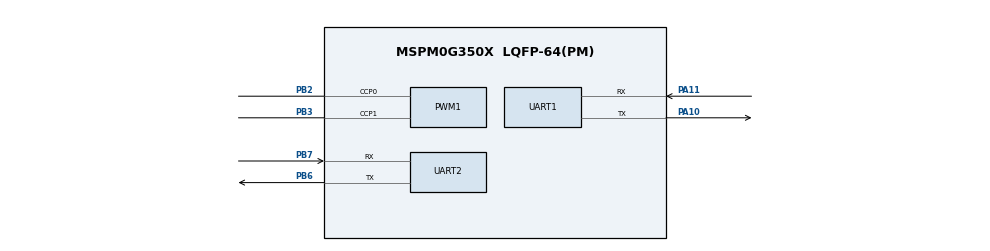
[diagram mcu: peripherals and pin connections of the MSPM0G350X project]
/**
 * @cliArgs --device "MSPM0G350X" --package "LQFP-64(PM)" --part "Default" --product "mspm0_sdk@2.01.00.03"
 * @versions {"tool":"1.20.0+3587"}
 */

/**
 * Import the modules used in this configuration.
 */
const Board   = scripting.addModule("/ti/driverlib/Board");
const GPIO    = scripting.addModule("/ti/driverlib/GPIO", {}, false);
const GPIO1   = GPIO.addInstance();
const GPIO2   = GPIO.addInstance();
const GPIO3   = GPIO.addInstance();
const GPIO4   = GPIO.addInstance();
const GPIO5   = GPIO.addInstance();
const GPIO6   = GPIO.addInstance();
const GPIO7   = GPIO.addInstance();
const GPIO8   = GPIO.addInstance();
const GPIO9   = GPIO.addInstance();
const GPIO10  = GPIO.addInstance();
const GPIO11  = GPIO.addInstance();
const GPIO12  = GPIO.addInstance();
const I2C     = scripting.addModule("/ti/driverlib/I2C", {}, false);
const I2C1    = I2C.addInstance();
const PWM     = scripting.addModule("/ti/driverlib/PWM", {}, false);
const PWM1    = PWM.addInstance();
const SYSCTL  = scripting.addModule("/ti/driverlib/SYSCTL");
const SYSTICK = scripting.addModule("/ti/driverlib/SYSTICK");
const TIMER   = scripting.addModule("/ti/driverlib/TIMER", {}, false);
const TIMER1  = TIMER.addInstance();
const UART    = scripting.addModule("/ti/driverlib/UART", {}, false);
const UART1   = UART.addInstance();
const UART2   = UART.addInstance();

/**
 * Write custom configuration values to the imported modules.
 */
const divider7       = system.clockTree["PLL_PDIV"];
divider7.divideValue = 2;

const divider9       = system.clockTree["UDIV"];
divider9.divideValue = 2;

const gate7  = system.clockTree["MFCLKGATE"];
gate7.enable = true;

const multiplier2         = system.clockTree["PLL_QDIV"];
multiplier2.multiplyValue = 5;

const mux8       = system.clockTree["HSCLKMUX"];
mux8.inputSelect = "HSCLKMUX_SYSPLL2X";

const pinFunction4     = system.clockTree["HFXT"];
pinFunction4.inputFreq = 40;
pinFunction4.enable    = true;


GPIO1.$name                          = "AIN";
GPIO1.associatedPins.create(2);
GPIO1.associatedPins[0].$name        = "AIN1";
GPIO1.associatedPins[0].assignedPort = "PORTA";
GPIO1.associatedPins[0].assignedPin  = "14";
GPIO1.associatedPins[1].$name        = "AIN2";
GPIO1.associatedPins[1].assignedPort = "PORTA";
GPIO1.associatedPins[1].assignedPin  = "13";

GPIO2.$name                          = "LED";
GPIO2.associatedPins[0].$name        = "led";
GPIO2.associatedPins[0].assignedPort = "PORTB";
GPIO2.associatedPins[0].assignedPin  = "9";

GPIO3.$name                          = "BIN";
GPIO3.associatedPins.create(2);
GPIO3.associatedPins[0].$name        = "BIN1";
GPIO3.associatedPins[0].assignedPin  = "17";
GPIO3.associatedPins[0].assignedPort = "PORTA";
GPIO3.associatedPins[1].$name        = "BIN2";
GPIO3.associatedPins[1].assignedPort = "PORTA";
GPIO3.associatedPins[1].assignedPin  = "16";

GPIO4.$name                         = "ENCODERA";
GPIO4.port                          = "PORTA";
GPIO4.associatedPins.create(2);
GPIO4.associatedPins[0].$name       = "E1A";
GPIO4.associatedPins[0].direction   = "INPUT";
GPIO4.associatedPins[0].assignedPin = "25";
GPIO4.associatedPins[0].interruptEn = true;
GPIO4.associatedPins[0].polarity    = "RISE";
GPIO4.associatedPins[1].$name       = "E1B";
GPIO4.associatedPins[1].direction   = "INPUT";
GPIO4.associatedPins[1].assignedPin = "26";
GPIO4.associatedPins[1].interruptEn = true;
GPIO4.associatedPins[1].polarity    = "RISE";

GPIO5.$name                         = "ENCODERB";
GPIO5.port                          = "PORTB";
GPIO5.associatedPins.create(2);
GPIO5.associatedPins[0].$name       = "E2A";
GPIO5.associatedPins[0].direction   = "INPUT";
GPIO5.associatedPins[0].assignedPin = "20";
GPIO5.associatedPins[0].interruptEn = true;
GPIO5.associatedPins[0].polarity    = "RISE";
GPIO5.associatedPins[1].$name       = "E2B";
GPIO5.associatedPins[1].direction   = "INPUT";
GPIO5.associatedPins[1].assignedPin = "24";
GPIO5.associatedPins[1].interruptEn = true;
GPIO5.associatedPins[1].polarity    = "RISE";

GPIO6.$name                          = "OLED_RST";
GPIO6.associatedPins[0].$name        = "PIN_RST";
GPIO6.associatedPins[0].assignedPort = "PORTB";
GPIO6.associatedPins[0].assignedPin  = "14";

GPIO7.$name                          = "OLED_DC";
GPIO7.associatedPins[0].$name        = "PIN_DC";
GPIO7.associatedPins[0].assignedPort = "PORTB";
GPIO7.associatedPins[0].assignedPin  = "15";

GPIO8.$name                          = "OLED_SCL";
GPIO8.associatedPins[0].$name        = "PIN_SCL";
GPIO8.associatedPins[0].assignedPort = "PORTA";
GPIO8.associatedPins[0].assignedPin  = "28";

GPIO9.$name                          = "OLED_SDA";
GPIO9.associatedPins[0].$name        = "PIN_SDA";
GPIO9.associatedPins[0].assignedPort = "PORTA";
GPIO9.associatedPins[0].assignedPin  = "31";

GPIO10.$name                          = "MPU_INT";
GPIO10.associatedPins[0].$name        = "INT";
GPIO10.associatedPins[0].direction    = "INPUT";
GPIO10.associatedPins[0].assignedPort = "PORTA";
GPIO10.associatedPins[0].assignedPin  = "7";
GPIO10.associatedPins[0].polarity     = "RISE";
GPIO10.associatedPins[0].interruptEn  = true;

GPIO11.$name                              = "TRACK";
GPIO11.associatedPins.create(7);
GPIO11.associatedPins[0].$name            = "S2";
GPIO11.associatedPins[0].direction        = "INPUT";
GPIO11.associatedPins[0].internalResistor = "PULL_UP";
GPIO11.associatedPins[0].assignedPort     = "PORTB";
GPIO11.associatedPins[0].assignedPin      = "16";
GPIO11.associatedPins[1].$name            = "S3";
GPIO11.associatedPins[1].assignedPort     = "PORTB";
GPIO11.associatedPins[1].direction        = "INPUT";
GPIO11.associatedPins[1].internalResistor = "PULL_UP";
GPIO11.associatedPins[1].assignedPin      = "17";
GPIO11.associatedPins[2].$name            = "S4";
GPIO11.associatedPins[2].internalResistor = "PULL_UP";
GPIO11.associatedPins[2].assignedPort     = "PORTA";
GPIO11.associatedPins[2].assignedPin      = "22";
GPIO11.associatedPins[2].direction        = "INPUT";
GPIO11.associatedPins[3].$name            = "S5";
GPIO11.associatedPins[3].direction        = "INPUT";
GPIO11.associatedPins[3].internalResistor = "PULL_UP";
GPIO11.associatedPins[3].assignedPort     = "PORTA";
GPIO11.associatedPins[3].assignedPin      = "24";
GPIO11.associatedPins[4].$name            = "S6";
GPIO11.associatedPins[4].internalResistor = "PULL_UP";
GPIO11.associatedPins[4].direction        = "INPUT";
GPIO11.associatedPins[4].assignedPort     = "PORTA";
GPIO11.associatedPins[4].assignedPin      = "27";
GPIO11.associatedPins[5].$name            = "S7";
GPIO11.associatedPins[5].direction        = "INPUT";
GPIO11.associatedPins[5].internalResistor = "PULL_UP";
GPIO11.associatedPins[5].assignedPort     = "PORTA";
GPIO11.associatedPins[5].assignedPin      = "9";
GPIO11.associatedPins[6].$name            = "S8";
GPIO11.associatedPins[6].direction        = "INPUT";
GPIO11.associatedPins[6].internalResistor = "PULL_UP";
GPIO11.associatedPins[6].assignedPort     = "PORTA";
GPIO11.associatedPins[6].assignedPin      = "12";

GPIO12.$name                              = "KEY";
GPIO12.associatedPins[0].$name            = "BUTTON";
GPIO12.associatedPins[0].direction        = "INPUT";
GPIO12.associatedPins[0].internalResistor = "PULL_UP";
GPIO12.associatedPins[0].assignedPort     = "PORTB";
GPIO12.associatedPins[0].assignedPin      = "8";

I2C1.$name                           = "I2C_0";
I2C1.basicEnableController           = true;
I2C1.basicControllerStandardBusSpeed = "Fast";
I2C1.sdaPinConfig.$name              = "ti_driverlib_gpio_GPIOPinGeneric4";
I2C1.sclPinConfig.$name              = "ti_driverlib_gpio_GPIOPinGeneric5";

PWM1.$name                      = "PWM_0";
PWM1.timerCount                 = 8000;
PWM1.pwmMode                    = "EDGE_ALIGN_UP";
PWM1.timerStartTimer            = true;
PWM1.peripheral.$assign         = "TIMA1";
PWM1.peripheral.ccp0Pin.$assign = "PB2";
PWM1.peripheral.ccp1Pin.$assign = "PB3";
PWM1.PWM_CHANNEL_0.$name        = "ti_driverlib_pwm_PWMTimerCC0";
PWM1.PWM_CHANNEL_1.$name        = "ti_driverlib_pwm_PWMTimerCC1";
PWM1.ccp0PinConfig.$name        = "ti_driverlib_gpio_GPIOPinGeneric0";
PWM1.ccp1PinConfig.$name        = "ti_driverlib_gpio_GPIOPinGeneric1";

SYSCTL.forceDefaultClkConfig = true;
SYSCTL.clockTreeEn           = true;

SYSTICK.systickEnable = true;
SYSTICK.periodEnable  = true;
SYSTICK.period        = 16777216;

TIMER1.$name            = "TIMER_0";
TIMER1.timerStartTimer  = true;
TIMER1.timerMode        = "PERIODIC_UP";
TIMER1.timerClkDiv      = 8;
TIMER1.timerClkPrescale = 255;
TIMER1.interrupts       = ["ZERO"];
TIMER1.timerPeriod      = "10ms";

UART1.$name                    = "UART_0";
UART1.targetBaudRate           = 115200;
UART1.peripheral.$assign       = "UART0";
UART1.peripheral.rxPin.$assign = "PA11";
UART1.peripheral.txPin.$assign = "PA10";
UART1.txPinConfig.$name        = "ti_driverlib_gpio_GPIOPinGeneric2";
UART1.rxPinConfig.$name        = "ti_driverlib_gpio_GPIOPinGeneric3";

UART2.$name                            = "UART_OPENMV";
UART2.targetBaudRate                   = 115200;
UART2.peripheral.rxPin.$assign         = "PB7";
UART2.peripheral.txPin.$assign         = "PB6";
UART2.txPinConfig.$name                = "ti_driverlib_gpio_GPIOPinGeneric6";
UART2.txPinConfig.direction            = scripting.forceWrite("OUTPUT");
UART2.txPinConfig.hideOutputInversion  = scripting.forceWrite(false);
UART2.txPinConfig.onlyInternalResistor = scripting.forceWrite(false);
UART2.txPinConfig.passedPeripheralType = scripting.forceWrite("Digital");
UART2.rxPinConfig.$name                = "ti_driverlib_gpio_GPIOPinGeneric7";
UART2.rxPinConfig.hideOutputInversion  = scripting.forceWrite(false);
UART2.rxPinConfig.onlyInternalResistor = scripting.forceWrite(false);
UART2.rxPinConfig.passedPeripheralType = scripting.forceWrite("Digital");

/**
 * Pinmux solution for unlocked pins/peripherals. This ensures that minor changes to the automatic solver in a future
 * version of the tool will not impact the pinmux you originally saw.  These lines can be completely deleted in order to
 * re-solve from scratch.
 */
pinFunction4.peripheral.$suggestSolution           = "SYSCTL";
pinFunction4.peripheral.hfxInPin.$suggestSolution  = "PA5";
pinFunction4.peripheral.hfxOutPin.$suggestSolution = "PA6";
Board.peripheral.$suggestSolution                  = "DEBUGSS";
Board.peripheral.swclkPin.$suggestSolution         = "PA20";
Board.peripheral.swdioPin.$suggestSolution         = "PA19";
GPIO1.associatedPins[0].pin.$suggestSolution       = "PA14";
GPIO1.associatedPins[1].pin.$suggestSolution       = "PA13";
GPIO2.associatedPins[0].pin.$suggestSolution       = "PB9";
GPIO3.associatedPins[0].pin.$suggestSolution       = "PA17";
GPIO3.associatedPins[1].pin.$suggestSolution       = "PA16";
GPIO4.associatedPins[0].pin.$suggestSolution       = "PA25";
GPIO4.associatedPins[1].pin.$suggestSolution       = "PA26";
GPIO5.associatedPins[0].pin.$suggestSolution       = "PB20";
GPIO5.associatedPins[1].pin.$suggestSolution       = "PB24";
GPIO6.associatedPins[0].pin.$suggestSolution       = "PB14";
GPIO7.associatedPins[0].pin.$suggestSolution       = "PB15";
GPIO8.associatedPins[0].pin.$suggestSolution       = "PA28";
GPIO9.associatedPins[0].pin.$suggestSolution       = "PA31";
GPIO10.associatedPins[0].pin.$suggestSolution      = "PA7";
GPIO11.associatedPins[0].pin.$suggestSolution      = "PB16";
GPIO11.associatedPins[1].pin.$suggestSolution      = "PB17";
GPIO11.associatedPins[2].pin.$suggestSolution      = "PA22";
GPIO11.associatedPins[3].pin.$suggestSolution      = "PA24";
GPIO11.associatedPins[4].pin.$suggestSolution      = "PA27";
GPIO11.associatedPins[5].pin.$suggestSolution      = "PA9";
GPIO11.associatedPins[6].pin.$suggestSolution      = "PA12";
GPIO12.associatedPins[0].pin.$suggestSolution      = "PB8";
I2C1.peripheral.$suggestSolution                   = "I2C0";
I2C1.peripheral.sdaPin.$suggestSolution            = "PA0";
I2C1.peripheral.sclPin.$suggestSolution            = "PA1";
TIMER1.peripheral.$suggestSolution                 = "TIMA0";
UART2.peripheral.$suggestSolution                  = "UART1";
